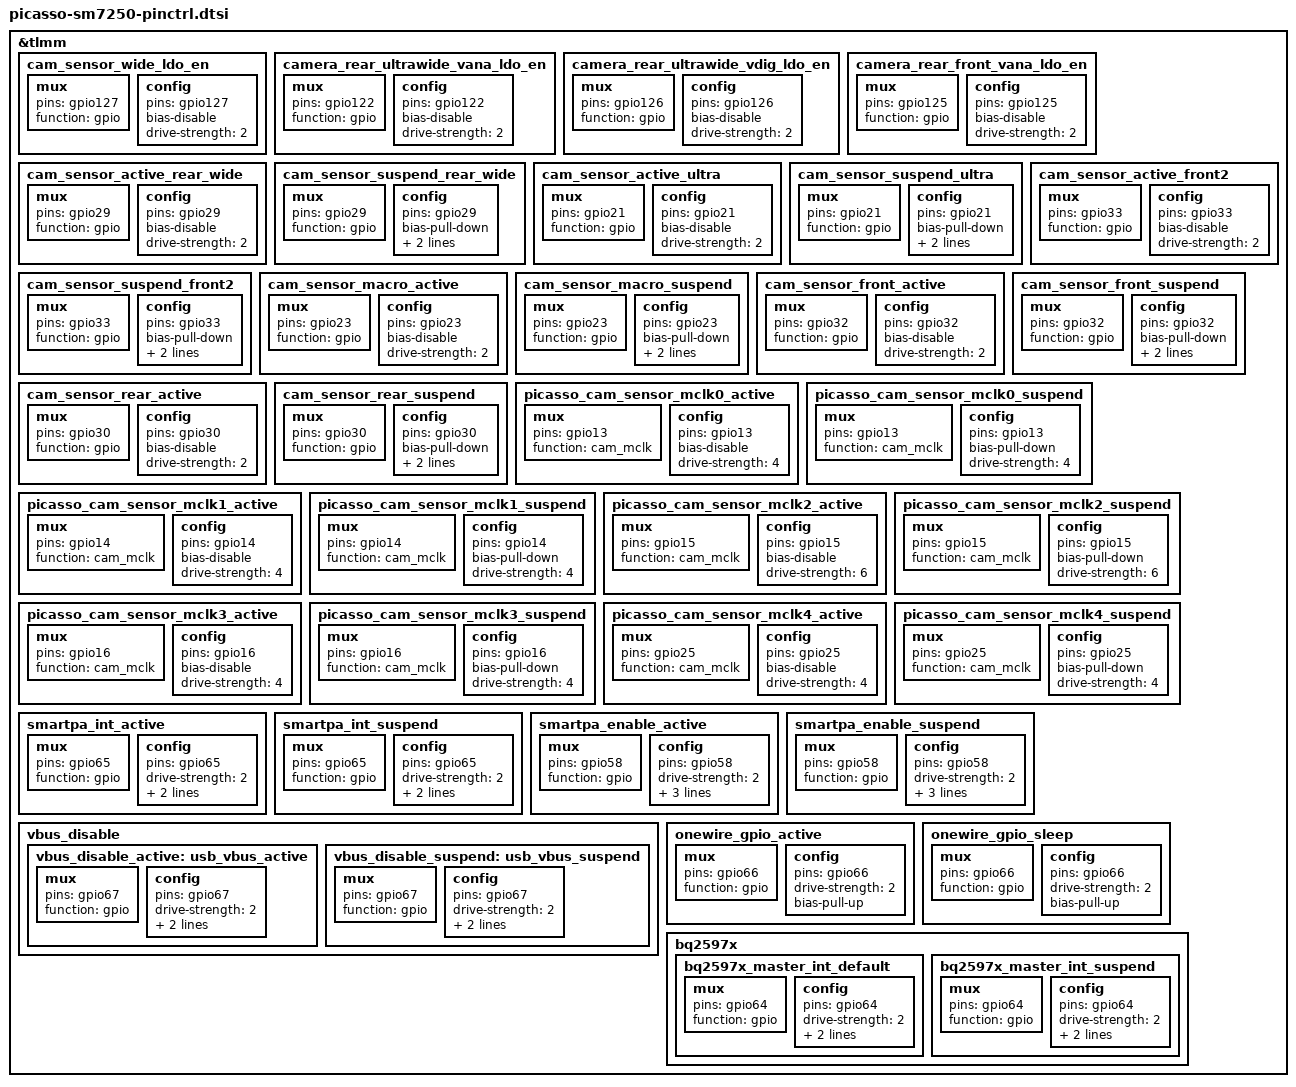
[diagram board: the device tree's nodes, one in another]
/* Copyright (c) 2018, The Linux Foundation. All rights reserved.
 * Copyright (C) 2021 XiaoMi, Inc.
 *
 * This program is free software; you can redistribute it and/or modify
 * it under the terms of the GNU General Public License version 2 and
 * only version 2 as published by the Free Software Foundation.
 *
 * This program is distributed in the hope that it will be useful,
 * but WITHOUT ANY WARRANTY; without even the implied warranty of
 * MERCHANTABILITY or FITNESS FOR A PARTICULAR PURPOSE.  See the
 * GNU General Public License for more details.
 */


/*for G7A SM7250 pinctrl*/

&tlmm {

	cam_sensor_wide_ldo_en: cam_sensor_wide_ldo_en {
		/* RESET REAR2 */
		mux {
			pins = "gpio127";
			function = "gpio";
		};

		config {
			pins = "gpio127";
			bias-disable; /* No PULL */
			drive-strength = <2>; /* 2 MA */
		};
	};

	camera_rear_ultrawide_vana_ldo_en: camera_rear_ultrawide_vana_ldo_en {
		mux {
			pins = "gpio122";
			function = "gpio";
		};

		config {
			pins = "gpio122";
			bias-disable; /* No PULL */
			drive-strength = <2>; /* 2 MA */
		};
	};

	camera_rear_ultrawide_vdig_ldo_en: camera_rear_ultrawide_vdig_ldo_en {
		mux {
			pins = "gpio126";
			function = "gpio";
		};

		config {
			pins = "gpio126";
			bias-disable; /* No PULL */
			drive-strength = <2>; /* 2 MA */
		};
	};

	camera_rear_front_vana_ldo_en: camera_rear_front_vana_ldo_en {
		mux {
			pins = "gpio125";
			function = "gpio";
		};

		config {
			pins = "gpio125";
			bias-disable; /* No PULL */
			drive-strength = <2>; /* 2 MA */
		};
	};

	cam_sensor_active_rear_wide: cam_sensor_active_rear_wide {
		/* RESET REAR2 */
		mux {
			pins = "gpio29";
			function = "gpio";
		};

		config {
			pins = "gpio29";
			bias-disable; /* No PULL */
			drive-strength = <2>; /* 2 MA */
		};
	};

	cam_sensor_suspend_rear_wide: cam_sensor_suspend_rear_wide {
		/* RESET REAR2 */
		mux {
			pins = "gpio29";
			function = "gpio";
		};

		config {
			pins = "gpio29";
			bias-pull-down; /* PULL DOWN */
			drive-strength = <2>; /* 2 MA */
			output-low;
		};
	};

	cam_sensor_active_ultra: cam_sensor_active_ultra {
		/* RESET ULTRA */
		mux {
			pins = "gpio21";
			function = "gpio";
		};

		config {
			pins = "gpio21";
			bias-disable; /* No PULL */
			drive-strength = <2>; /* 2 MA */
		};
	};

	cam_sensor_suspend_ultra: cam_sensor_suspend_ultra {
		/* RESET ULTRA */
		mux {
			pins = "gpio21";
			function = "gpio";
		};

		config {
			pins = "gpio21";
			bias-pull-down; /* PULL DOWN */
			drive-strength = <2>; /* 2 MA */
			output-low;
		};
	};

	cam_sensor_active_front2: cam_sensor_active_front2 {
		/* RESET FRONT */
		mux {
			pins = "gpio33";
			function = "gpio";
		};

		config {
			pins = "gpio33";
			bias-disable; /* No PULL */
			drive-strength = <2>; /* 2 MA */
		};
	};

	cam_sensor_suspend_front2: cam_sensor_suspend_front2 {
		/* RESET FRONT */
		mux {
			pins = "gpio33";
			function = "gpio";
		};

		config {
			pins = "gpio33";
			bias-pull-down; /* PULL DOWN */
			drive-strength = <2>; /* 2 MA */
			output-low;
		};
	};

	cam_sensor_macro_active: cam_sensor_macro_active {
		/* MACRO RESET */
		mux {
			pins = "gpio23";
			function = "gpio";
		};

		config {
			pins = "gpio23";
			bias-disable; /* No PULL */
			drive-strength = <2>; /* 2 MA */
		};
	};

	cam_sensor_macro_suspend: cam_sensor_macro_suspend {
		/* MACRO RESET */
		mux {
			pins = "gpio23";
			function = "gpio";
		};

		config {
			pins = "gpio23";
			bias-pull-down; /* PULL DOWN */
			drive-strength = <2>; /* 2 MA */
			output-low;
		};
	};

	cam_sensor_front_active: cam_sensor_front_active {
		/* RESET FRONT */
		mux {
			pins = "gpio32";
			function = "gpio";
		};

		config {
			pins = "gpio32";
			bias-disable; /* No PULL */
			drive-strength = <2>; /* 2 MA */
		};
	};

	cam_sensor_front_suspend: cam_sensor_front_suspend {
		/* RESET FRONT */
		mux {
			pins = "gpio32";
			function = "gpio";
		};

		config {
			pins = "gpio32";
			bias-pull-down; /* PULL DOWN */
			drive-strength = <2>; /* 2 MA */
			output-low;
		};
	};

	cam_sensor_rear_active: cam_sensor_rear_active {
		/* RESET REAR2 */
		mux {
			pins = "gpio30";
			function = "gpio";
		};

		config {
			pins = "gpio30";
			bias-disable; /* No PULL */
			drive-strength = <2>; /* 2 MA */
		};
	};

	cam_sensor_rear_suspend: cam_sensor_rear_suspend {
		/* RESET REAR2 */
		mux {
			pins = "gpio30";
			function = "gpio";
		};

		config {
			pins = "gpio30";
			bias-pull-down; /* PULL DOWN */
			drive-strength = <2>; /* 2 MA */
			output-low;
		};
	};

	picasso_cam_sensor_mclk0_active: picasso_cam_sensor_mclk0_active {
		/* MCLK0 */
		mux {
			pins = "gpio13";
			function = "cam_mclk";
		};

		config {
			pins = "gpio13";
			bias-disable; /* No PULL */
			drive-strength = <4>; /* 4 MA */
		};
	};

	picasso_cam_sensor_mclk0_suspend: picasso_cam_sensor_mclk0_suspend {
		/* MCLK0 */
		mux {
			pins = "gpio13";
			function = "cam_mclk";
		};

		config {
			pins = "gpio13";
			bias-pull-down; /* PULL DOWN */
			drive-strength = <4>; /* 4 MA */
		};
	};

	picasso_cam_sensor_mclk1_active: picasso_cam_sensor_mclk1_active {
		/* MCLK1 */
		mux {
			pins = "gpio14";
			function = "cam_mclk";
		};

		config {
			pins = "gpio14";
			bias-disable; /* No PULL */
			drive-strength = <4>; /* 4 MA */
		};
	};

	picasso_cam_sensor_mclk1_suspend: picasso_cam_sensor_mclk1_suspend {
		/* MCLK1 */
		mux {
			pins = "gpio14";
			function = "cam_mclk";
		};

		config {
			pins = "gpio14";
			bias-pull-down; /* PULL DOWN */
			drive-strength = <4>; /* 4 MA */
		};
	};

	picasso_cam_sensor_mclk2_active: picasso_cam_sensor_mclk2_active {
		/* MCLK2 */
		mux {
			pins = "gpio15";
			function = "cam_mclk";
		};

		config {
			pins = "gpio15";
			bias-disable; /* No PULL */
			drive-strength = <6>; /* 6 MA */
		};
	};

	picasso_cam_sensor_mclk2_suspend: picasso_cam_sensor_mclk2_suspend {
		/* MCLK2 */
		mux {
			pins = "gpio15";
			function = "cam_mclk";
		};

		config {
			pins = "gpio15";
			bias-pull-down; /* PULL DOWN */
			drive-strength = <6>; /* 6 MA */
		};
	};

	picasso_cam_sensor_mclk3_active: picasso_cam_sensor_mclk3_active {
		/* MCLK3 */
		mux {
			pins = "gpio16";
			function = "cam_mclk";
		};

		config {
			pins = "gpio16";
			bias-disable; /* No PULL */
			drive-strength = <4>; /* 4 MA */
		};
	};

	picasso_cam_sensor_mclk3_suspend: picasso_cam_sensor_mclk3_suspend {
		/* MCLK3 */
		mux {
			pins = "gpio16";
			function = "cam_mclk";
		};

		config {
			pins = "gpio16";
			bias-pull-down; /* PULL DOWN */
			drive-strength = <4>; /* 4 MA */
		};
	};

	picasso_cam_sensor_mclk4_active: picasso_cam_sensor_mclk4_active {
		/* MCLK4 */
		mux {
			pins = "gpio25";
			function = "cam_mclk";
		};

		config {
			pins = "gpio25";
			bias-disable; /* No PULL */
			drive-strength = <4>; /* 4 MA */
		};
	};

	picasso_cam_sensor_mclk4_suspend: picasso_cam_sensor_mclk4_suspend {
		/* MCLK4 */
		mux {
			pins = "gpio25";
			function = "cam_mclk";
		};

		config {
			pins = "gpio25";
			bias-pull-down; /* PULL DOWN */
			drive-strength = <4>; /* 4 MA */
		};
	};

	smartpa_int_active: smartpa_int_active {
		/* active state */
		mux {
			/* GPIO 65 Interrupt */
			pins = "gpio65";
			function = "gpio";
		};

		config {
			pins = "gpio65";
			drive-strength = <2>; /* 2 MA */
			bias-pull-up;
			input-enable;
		};
	};

	smartpa_int_suspend: smartpa_int_suspend {
		/* sleep state */
		mux {
			/* GPIO 65 Interrupt */
			pins = "gpio65";
			function = "gpio";
		};

		config {
			pins = "gpio65";
			drive-strength = <2>; /* 2 MA */
			bias-pull-up;
			input-enable;
		};
	};

	smartpa_enable_active: smartpa_enable_active {
		/* active state */
		mux {
			/* GPIO 66 rst pin */
			pins = "gpio58";
			function = "gpio";
		};

		config {
			pins = "gpio58";
			drive-strength = <2>;
			bias-disable;
			bias-pull-down;
			output-low;
		};
	};

	smartpa_enable_suspend: smartpa_enable_suspend {
		/* sleep state */
		mux {
			/* GPIO 66 rst pin */
			pins = "gpio58";
			function = "gpio";
		};

		config {
			pins = "gpio58";
			drive-strength = <2>;
			bias-disable;
			bias-pull-down;
			output-low;
		};
	};

	vbus_disable {
		vbus_disable_active: usb_vbus_active {
			/* active state */
			mux {
				pins = "gpio67";
				function = "gpio";
			};

			config {
				pins = "gpio67";
				drive-strength = <2>; /* 2 MA */
				bias-pull-up;
				output-high;
			};
		};

		vbus_disable_suspend: usb_vbus_suspend {
			mux {
				pins = "gpio67";
				function = "gpio";
			};

			config {
				pins = "gpio67";
				drive-strength = <2>; /* 2 MA */
				bias-pull-down;
				output-low;
			};
		};
	};

	onewire_gpio_active: onewire_gpio_active {
		mux {
			pins = "gpio66";
			function = "gpio";
		};

		config {
			pins = "gpio66";
			drive-strength = <2>;
			bias-pull-up; /* No PULL */
		};
	};

	onewire_gpio_sleep: onewire_gpio_sleep {
		mux {
			pins = "gpio66";
			function = "gpio";
		};

		config {
			pins = "gpio66";
			drive-strength = <2>;
			bias-pull-up;
		};
	};

	bq2597x {
		bq2597x_master_int_default: bq2597x_master_int_default {
			/* active state */
			mux {
				/* GPIO 64 is used for bq25970 master ic interrupt usage */
				pins = "gpio64";
				function = "gpio";
			};

			config {
				pins = "gpio64";
				drive-strength = <2>; /* 2 MA */
				bias-pull-up;
				input-enable;
			};
		};

		bq2597x_master_int_suspend: bq2597x_master_int_suspend {
			/* sleep state */
			mux {
				/* GPIO 64 is used for bq25970 master ic interrupt usage */
				pins = "gpio64";
				function = "gpio";
			};

			config {
				pins = "gpio64";
				drive-strength = <2>; /* 2 MA */
				bias-pull-up;
				input-enable;
			};
		};
	};
};

